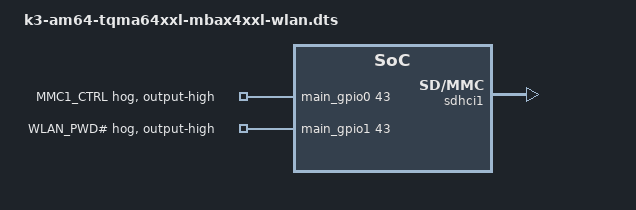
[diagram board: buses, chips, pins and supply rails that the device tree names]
// SPDX-License-Identifier: GPL-2.0-only
/*
 * Copyright (C) 2022 TQ-Systems GmbH
 */

/dts-v1/;
/plugin/;

&sdhci1 {
	no-sd;
	status = "okay";
};

&main_gpio0 {
	line43 {
		gpio-hog;
		gpios = <43 0>;
		line-name = "MMC1_CTRL";
		output-high;
	};
};

&main_gpio1 {
	line43 {
		gpio-hog;
		gpios = <43 0>;
		line-name = "WLAN_PWD#";
		output-high;
	};
};
